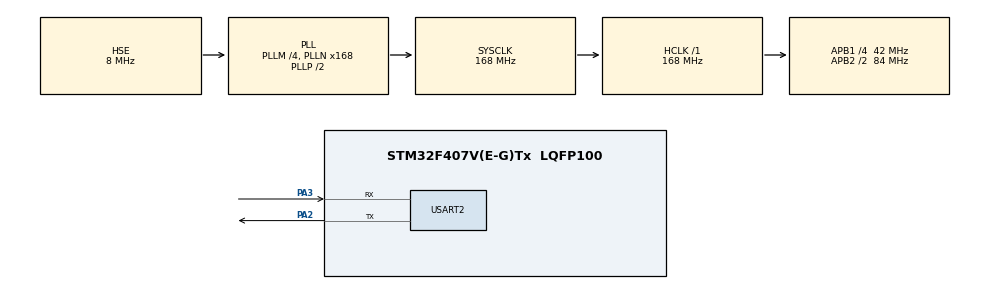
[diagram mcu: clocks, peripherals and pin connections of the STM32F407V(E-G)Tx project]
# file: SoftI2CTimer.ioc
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Mcu.Family=STM32F4
Mcu.Name=STM32F407V(E-G)Tx
Mcu.Package=LQFP100
NVIC.PriorityGroup=NVIC_PRIORITYGROUP_4
NVIC.TIM7_IRQn=true\:0\:0\:false\:false\:true\:true\:true\:true
PA2.Mode=Asynchronous
PA2.Signal=USART2_TX
PA3.Mode=Asynchronous
PA3.Signal=USART2_RX
PH0-OSC_IN.Mode=HSE-External-Oscillator
PH0-OSC_IN.Signal=RCC_OSC_IN
PH1-OSC_OUT.Mode=HSE-External-Oscillator
PH1-OSC_OUT.Signal=RCC_OSC_OUT
ProjectManager.HeapSize=0x200
ProjectManager.StackSize=0x400
ProjectManager.TargetToolchain=MDK-ARM V5.32
RCC.48MHZClocksFreq_Value=84000000
RCC.AHBFreq_Value=168000000
RCC.APB1CLKDivider=RCC_HCLK_DIV4
RCC.APB1Freq_Value=42000000
RCC.APB1TimFreq_Value=84000000
RCC.APB2CLKDivider=RCC_HCLK_DIV2
RCC.APB2Freq_Value=84000000
RCC.APB2TimFreq_Value=168000000
RCC.CortexFreq_Value=168000000
RCC.HCLKFreq_Value=168000000
RCC.HSE_VALUE=8000000
RCC.HSI_VALUE=16000000
RCC.LSE_VALUE=32768
RCC.PLLM=4
RCC.PLLN=168
RCC.PLLSourceVirtual=RCC_PLLSOURCE_HSE
RCC.SYSCLKFreq_VALUE=168000000
RCC.SYSCLKSource=RCC_SYSCLKSOURCE_PLLCLK
RCC.VCOOutputFreq_Value=336000000
TIM7.Period=40
TIM7.Prescaler=21
USART2.VirtualMode=VM_ASYNC
VP_TIM7_VS_ClockSourceINT.Mode=Enable_Timer
board=custom

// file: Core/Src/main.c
/* USER CODE BEGIN Header */
/**
  ******************************************************************************
  * @file           : main.c
  * @brief          : Main program body
  ******************************************************************************
  * @attention
  *
  * Copyright (c) 2023 STMicroelectronics.
  * All rights reserved.
  *
  * This software is licensed under terms that can be found in the LICENSE file
  * in the root directory of this software component.
  * If no LICENSE file comes with this software, it is provided AS-IS.
  *
  ******************************************************************************
  */
/* USER CODE END Header */
#include "main.h"

/* USER CODE BEGIN Includes */
#include "printf.h"
#include "soft_i2c_timer.h"
/* USER CODE END Includes */

TIM_HandleTypeDef htim7;

UART_HandleTypeDef huart2;

void SystemClock_Config(void);
static void MX_GPIO_Init(void);
static void MX_TIM7_Init(void);
static void MX_USART2_UART_Init(void);
static void MX_GPIO_InitMy(void);

/* USER CODE BEGIN 0 */
int putchar(char c)
{
    while(!__HAL_UART_GET_FLAG(&huart2, UART_FLAG_TXE)){}

     HAL_UART_Transmit(&huart2, (uint8_t *)&c, 1, 1000);
		return 0;
}
/* USER CODE END 0 */

int main(void)
{

  /* MCU Configuration--------------------------------------------------------*/

  /* Reset of all peripherals, Initializes the Flash interface and the Systick. */
  HAL_Init();

  /* Configure the system clock */
  SystemClock_Config();

  /* Initialize all configured peripherals */
  MX_GPIO_Init();
  MX_TIM7_Init();
  MX_USART2_UART_Init();
  /* USER CODE BEGIN 2 */
	MX_GPIO_InitMy();
	printf("Soft I2C timer\n\r");
	Soft_I2C_Init();
	uint8_t reg[] = {20,21,22,23,24,25};
	//Soft_I2C_MemWrite(0x68, 25, reg, 6);

	uint8_t readReg;

	Soft_I2C_MemRead(0x68, 0x75, &readReg, 1);
  /* USER CODE END 2 */

  /* Infinite loop */
  while (1)
  {

  }
}

void SystemClock_Config(void)
{
  RCC_OscInitTypeDef RCC_OscInitStruct = {0};
  RCC_ClkInitTypeDef RCC_ClkInitStruct = {0};

  /** Configure the main internal regulator output voltage
  */
  __HAL_RCC_PWR_CLK_ENABLE();
  __HAL_PWR_VOLTAGESCALING_CONFIG(PWR_REGULATOR_VOLTAGE_SCALE1);

  /** Initializes the RCC Oscillators according to the specified parameters
  * in the RCC_OscInitTypeDef structure.
  */
  RCC_OscInitStruct.OscillatorType = RCC_OSCILLATORTYPE_HSE;
  RCC_OscInitStruct.HSEState = RCC_HSE_ON;
  RCC_OscInitStruct.PLL.PLLState = RCC_PLL_ON;
  RCC_OscInitStruct.PLL.PLLSource = RCC_PLLSOURCE_HSE;
  RCC_OscInitStruct.PLL.PLLM = 4;
  RCC_OscInitStruct.PLL.PLLN = 168;
  RCC_OscInitStruct.PLL.PLLP = RCC_PLLP_DIV2;
  RCC_OscInitStruct.PLL.PLLQ = 4;
  if (HAL_RCC_OscConfig(&RCC_OscInitStruct) != HAL_OK)
  {
    Error_Handler();
  }

  /** Initializes the CPU, AHB and APB buses clocks
  */
  RCC_ClkInitStruct.ClockType = RCC_CLOCKTYPE_HCLK|RCC_CLOCKTYPE_SYSCLK
                              |RCC_CLOCKTYPE_PCLK1|RCC_CLOCKTYPE_PCLK2;
  RCC_ClkInitStruct.SYSCLKSource = RCC_SYSCLKSOURCE_PLLCLK;
  RCC_ClkInitStruct.AHBCLKDivider = RCC_SYSCLK_DIV1;
  RCC_ClkInitStruct.APB1CLKDivider = RCC_HCLK_DIV4;
  RCC_ClkInitStruct.APB2CLKDivider = RCC_HCLK_DIV2;

  if (HAL_RCC_ClockConfig(&RCC_ClkInitStruct, FLASH_LATENCY_5) != HAL_OK)
  {
    Error_Handler();
  }
}

static void MX_TIM7_Init(void)
{

  TIM_MasterConfigTypeDef sMasterConfig = {0};

  htim7.Instance = TIM7;
  htim7.Init.Prescaler = 10 - 1;
  htim7.Init.CounterMode = TIM_COUNTERMODE_UP;
  htim7.Init.Period = 42 - 1;
  htim7.Init.AutoReloadPreload = TIM_AUTORELOAD_PRELOAD_DISABLE;
  if (HAL_TIM_Base_Init(&htim7) != HAL_OK)
  {
    Error_Handler();
  }
  sMasterConfig.MasterOutputTrigger = TIM_TRGO_RESET;
  sMasterConfig.MasterSlaveMode = TIM_MASTERSLAVEMODE_DISABLE;
  if (HAL_TIMEx_MasterConfigSynchronization(&htim7, &sMasterConfig) != HAL_OK)
  {
    Error_Handler();
  }

}

static void MX_USART2_UART_Init(void)
{

  huart2.Instance = USART2;
  huart2.Init.BaudRate = 115200;
  huart2.Init.WordLength = UART_WORDLENGTH_8B;
  huart2.Init.StopBits = UART_STOPBITS_1;
  huart2.Init.Parity = UART_PARITY_NONE;
  huart2.Init.Mode = UART_MODE_TX_RX;
  huart2.Init.HwFlowCtl = UART_HWCONTROL_NONE;
  huart2.Init.OverSampling = UART_OVERSAMPLING_16;
  if (HAL_UART_Init(&huart2) != HAL_OK)
  {
    Error_Handler();
  }

}

static void MX_GPIO_Init(void)
{

  /* GPIO Ports Clock Enable */
  __HAL_RCC_GPIOH_CLK_ENABLE();
  __HAL_RCC_GPIOA_CLK_ENABLE();

}

/* USER CODE BEGIN 4 */
static void MX_GPIO_InitMy(void)
{
  GPIO_InitTypeDef GPIO_InitStruct = {0};
/* USER CODE BEGIN MX_GPIO_Init_1 */
/* USER CODE END MX_GPIO_Init_1 */

  /* GPIO Ports Clock Enable */
  __HAL_RCC_GPIOH_CLK_ENABLE();
  __HAL_RCC_GPIOA_CLK_ENABLE();
  __HAL_RCC_GPIOB_CLK_ENABLE();

  /*Configure GPIO pin Output Level */
  HAL_GPIO_WritePin(GPIOB, GPIO_PIN_6|GPIO_PIN_7, GPIO_PIN_RESET);

  /*Configure GPIO pins : PB6 PB7 */
  GPIO_InitStruct.Pin = GPIO_PIN_6|GPIO_PIN_7;
  GPIO_InitStruct.Mode = GPIO_MODE_OUTPUT_PP;
  GPIO_InitStruct.Pull = GPIO_NOPULL;
  GPIO_InitStruct.Speed = GPIO_SPEED_FREQ_LOW;
  //HAL_GPIO_Init(GPIOB, &GPIO_InitStruct);

/* USER CODE BEGIN MX_GPIO_Init_2 */
/* USER CODE END MX_GPIO_Init_2 */
}
/* USER CODE END 4 */

void Error_Handler(void)
{
  __disable_irq();
  while (1)
  {
  }
}
